# f29h85x_hsm_sha_p_regs register map
Vendor: Texas Instruments
Peripheral module from a debugger description file (folder HSM).
Registers are 32-bit, read-write, no defined reset value unless marked. A register's access mark holds for its fields unless they carry their own. Offsets are as the file gives them; lines under a group give offsets from that group; [hi:lo] are bit positions; {n}, {i} and the like mark numbered series; 'fields as' and 'values as' point back to an identical list; <NAME> marks a mode.

## HSM_SHA_P — HSM SHA P Registers
0x00 P_ODIGEST_A
  [31:0] DATA
0x04 P_ODIGEST_B
  [31:0] DATA
0x08 P_ODIGEST_C
  [31:0] DATA
0x0C P_ODIGEST_D
  [31:0] DATA
0x10 P_ODIGEST_E
  [31:0] DATA
0x14 P_ODIGEST_F
  [31:0] DATA
0x18 P_ODIGEST_G
  [31:0] DATA
0x1C P_ODIGEST_H
  [31:0] DATA
0x20 P_IDIGEST_A
  [31:0] DATA
0x24 P_IDIGEST_B
  [31:0] DATA
0x28 P_IDIGEST_C
  [31:0] DATA
0x2C P_IDIGEST_D
  [31:0] DATA
0x30 P_IDIGEST_E
  [31:0] DATA
0x34 P_IDIGEST_F
  [31:0] DATA
0x38 P_IDIGEST_G
  [31:0] DATA
0x3C P_IDIGEST_H
  [31:0] DATA
0x40 P_DIGEST_COUNT
  [31:0] DATA
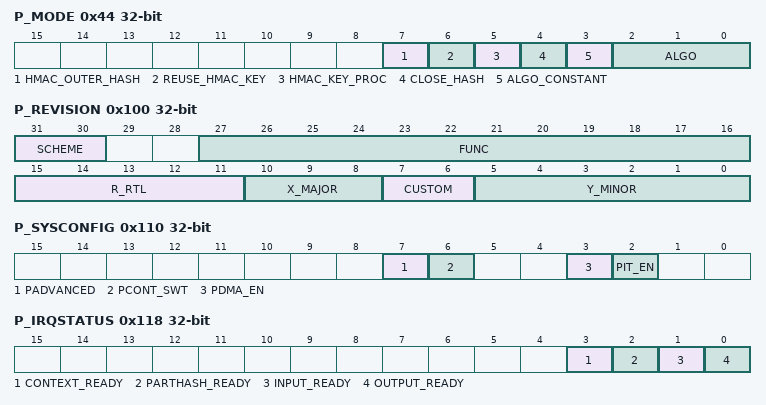
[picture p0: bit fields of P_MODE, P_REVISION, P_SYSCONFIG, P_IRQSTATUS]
0x44 P_MODE access per field
  [7] HMAC_OUTER_HASH rw, [6] REUSE_HMAC_KEY rw, [5] HMAC_KEY_PROC rw, [4] CLOSE_HASH rw, [3] ALGO_CONSTANT rw, [2:0] ALGO rw
0x48 P_LENGTH
  [31:0] DATA
{0x80+4i} P_DATA{i}_IN (i=0..31)
  [31:0] DATA{i}_IN
0x100 P_REVISION ro
  [31:30] SCHEME, [27:16] FUNC, [15:11] R_RTL, [10:8] X_MAJOR, [7:6] CUSTOM, [5:0] Y_MINOR
0x110 P_SYSCONFIG access per field
  [7] PADVANCED rw, [6] PCONT_SWT rw, [3] PDMA_EN rw, [2] PIT_EN rw
0x114 P_SYSSTATUS ro
  [0] RESETDONE
0x118 P_IRQSTATUS ro
  [3] CONTEXT_READY, [2] PARTHASH_READY, [1] INPUT_READY, [0] OUTPUT_READY
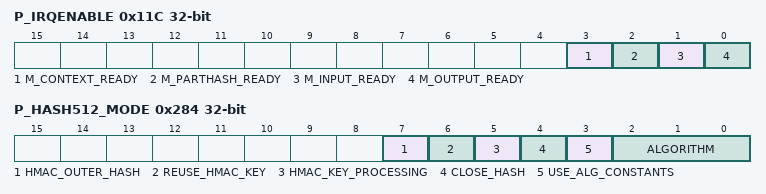
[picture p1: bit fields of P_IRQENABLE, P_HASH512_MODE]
0x11C P_IRQENABLE access per field
  [3] M_CONTEXT_READY rw, [2] M_PARTHASH_READY rw, [1] M_INPUT_READY rw, [0] M_OUTPUT_READY rw
0x200 P_HASH512_ODIGEST_A
  [31:0] ODIGEST_A
0x204 P_HASH512_ODIGEST_B
  [31:0] ODIGEST_B
0x208 P_HASH512_ODIGEST_C
  [31:0] ODIGEST_C
0x20C P_HASH512_ODIGEST_D
  [31:0] ODIGEST_D
0x210 P_HASH512_ODIGEST_E
  [31:0] ODIGEST_E
0x214 P_HASH512_ODIGEST_F
  [31:0] ODIGEST_F
0x218 P_HASH512_ODIGEST_G
  [31:0] ODIGEST_G
0x21C P_HASH512_ODIGEST_H
  [31:0] ODIGEST_H
0x220 P_HASH512_ODIGEST_I
  [31:0] ODIGEST_I
0x224 P_HASH512_ODIGEST_J
  [31:0] ODIGEST_J
0x228 P_HASH512_ODIGEST_K
  [31:0] ODIGEST_K
0x22C P_HASH512_ODIGEST_L
  [31:0] ODIGEST_L
0x230 P_HASH512_ODIGEST_M
  [31:0] ODIGEST_M
0x234 P_HASH512_ODIGEST_N
  [31:0] ODIGEST_N
0x238 P_HASH512_ODIGEST_O
  [31:0] ODIGEST_O
0x23C P_HASH512_ODIGEST_P
  [31:0] ODIGEST_P
0x240 P_HASH512_IDIGEST_A
  [31:0] IDIGEST_A
0x244 P_HASH512_IDIGEST_B
  [31:0] IDIGEST_B
0x248 P_HASH512_IDIGEST_C
  [31:0] IDIGEST_C
0x24C P_HASH512_IDIGEST_D
  [31:0] IDIGEST_D
0x250 P_HASH512_IDIGEST_E
  [31:0] IDIGEST_E
0x254 P_HASH512_IDIGEST_F
  [31:0] IDIGEST_F
0x258 P_HASH512_IDIGEST_G
  [31:0] IDIGEST_G
0x25C P_HASH512_IDIGEST_H
  [31:0] IDIGEST_H
0x260 P_HASH512_IDIGEST_I
  [31:0] IDIGEST_I
0x264 P_HASH512_IDIGEST_J
  [31:0] IDIGEST_J
0x268 P_HASH512_IDIGEST_K
  [31:0] IDIGEST_K
0x26C P_HASH512_IDIGEST_L
  [31:0] IDIGEST_L
0x270 P_HASH512_IDIGEST_M
  [31:0] IDIGEST_M
0x274 P_HASH512_IDIGEST_N
  [31:0] IDIGEST_N
0x278 P_HASH512_IDIGEST_O
  [31:0] IDIGEST_O
0x27C P_HASH512_IDIGEST_P
  [31:0] IDIGEST_P
0x280 P_HASH512_DIGEST_COUNT
  [31:0] DIGEST_COUNT
0x284 P_HASH512_MODE access per field
  [7] HMAC_OUTER_HASH rw, [6] REUSE_HMAC_KEY rw, [5] HMAC_KEY_PROCESSING rw, [4] CLOSE_HASH rw, [3] USE_ALG_CONSTANTS rw, [2:0] ALGORITHM rw
0x288 P_HASH512_LENGTH
